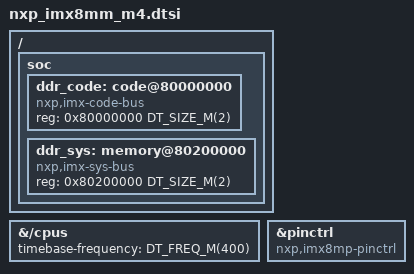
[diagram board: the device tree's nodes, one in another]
/*
 * Copyright (c) 2019, Manivannan Sadhasivam
 *
 * SPDX-License-Identifier: Apache-2.0
 */

#include <nxp/imx/nxp_imx8m_m4.dtsi>

/ {
	soc {
		ddr_code: code@80000000 {
			compatible = "nxp,imx-code-bus";
			reg = <0x80000000 DT_SIZE_M(2)>;
			device_type = "memory";
		};

		ddr_sys: memory@80200000 {
			compatible = "nxp,imx-sys-bus";
			reg = <0x80200000 DT_SIZE_M(2)>;
			device_type = "memory";
		};
	};
};

&{/cpus} {
	timebase-frequency = <DT_FREQ_M(400)>;
};

&pinctrl {
	compatible = "nxp,imx8mp-pinctrl";
	status = "okay";
};
